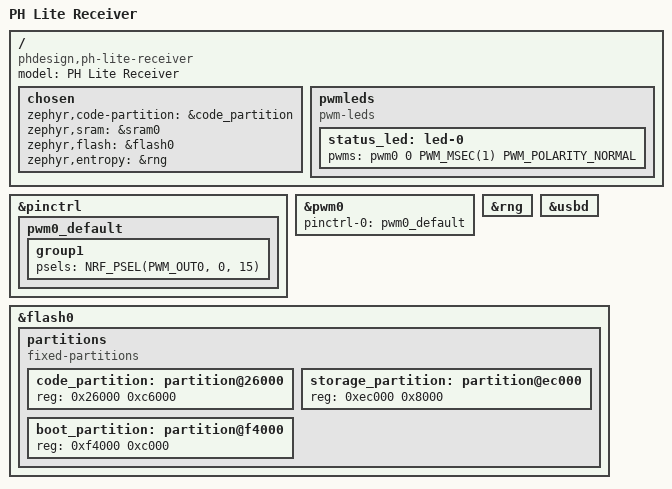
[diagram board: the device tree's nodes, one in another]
/* SPDX-License-Identifier: MIT */

/dts-v1/;
#include <nordic/nrf52840_qiaa.dtsi>
#include <zephyr/dt-bindings/pwm/pwm.h>

/ {
    model = "PH Lite Receiver";
    compatible = "phdesign,ph-lite-receiver";

    chosen {
        zephyr,code-partition = &code_partition;
        zephyr,sram = &sram0;
        zephyr,flash = &flash0;
        zephyr,entropy = &rng;
    };

    pwmleds {
        compatible = "pwm-leds";
        status_led: led-0 {
            pwms = <&pwm0 0 PWM_MSEC(1) PWM_POLARITY_NORMAL>;
        };
    };
};

&pinctrl {
    pwm0_default: pwm0_default {
        group1 { psels = <NRF_PSEL(PWM_OUT0, 0, 15)>; };
    };
};

&pwm0 {
    status = "okay";
    pinctrl-0 = <&pwm0_default>;
    pinctrl-names = "default";
};

&rng { status = "okay"; };

zephyr_udc0: &usbd { status = "okay"; };

&flash0 {
    partitions {
        compatible = "fixed-partitions";
        #address-cells = <1>;
        #size-cells = <1>;

        code_partition: partition@26000 {
            reg = <0x26000 0xc6000>;
        };

        storage_partition: partition@ec000 {
            reg = <0xec000 0x8000>;
        };

        boot_partition: partition@f4000 {
            reg = <0xf4000 0xc000>;
        };
    };
};
